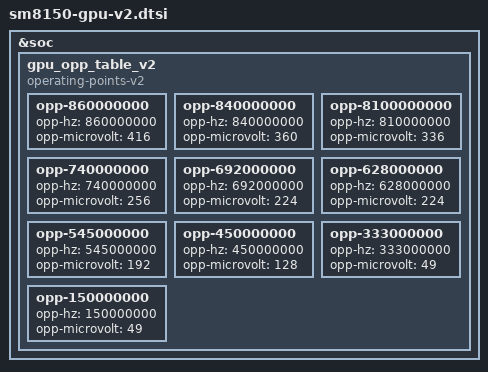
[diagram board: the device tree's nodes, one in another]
/* Copyright (c) 2018-2019, The Linux Foundation. All rights reserved.
 *
 * This program is free software; you can redistribute it and/or modify
 * it under the terms of the GNU General Public License version 2 and
 * only version 2 as published by the Free Software Foundation.
 *
 * This program is distributed in the hope that it will be useful,
 * but WITHOUT ANY WARRANTY; without even the implied warranty of
 * MERCHANTABILITY or FITNESS FOR A PARTICULAR PURPOSE.  See the
 * GNU General Public License for more details.
 */

&soc {
	gpu_opp_table_v2: gpu_opp_table_v2 {
		compatible = "operating-points-v2";

		opp-860000000 {
			opp-hz = /bits/ 64 <860000000>;
			opp-microvolt = <416>;
		};

		opp-840000000 {
			opp-hz = /bits/ 64 <840000000>;
			opp-microvolt = <360>;
		};

		opp-8100000000 {
			opp-hz = /bits/ 64 <810000000>;
			opp-microvolt = <336>;
		};

		opp-740000000 {
			opp-hz = /bits/ 64 <740000000>;
			opp-microvolt = <256>;
		};

		opp-692000000 {
			opp-hz = /bits/ 64 <692000000>;
			opp-microvolt = <224>;
		};

		opp-628000000 {
			opp-hz = /bits/ 64 <628000000>;
			opp-microvolt = <224>;
		};

		opp-545000000 {
			opp-hz = /bits/ 64 <545000000>;
			opp-microvolt = <192>;
		};

		opp-450000000 {
			opp-hz = /bits/ 64 <450000000>;
			opp-microvolt = <128>;
		};

                opp-333000000 {
                        opp-hz = /bits/ 64 <333000000>;
                        opp-microvolt = <49>;
                };

                opp-150000000 {
                        opp-hz = /bits/ 64 <150000000>;
                        opp-microvolt = <49>;
                };
	};
};
